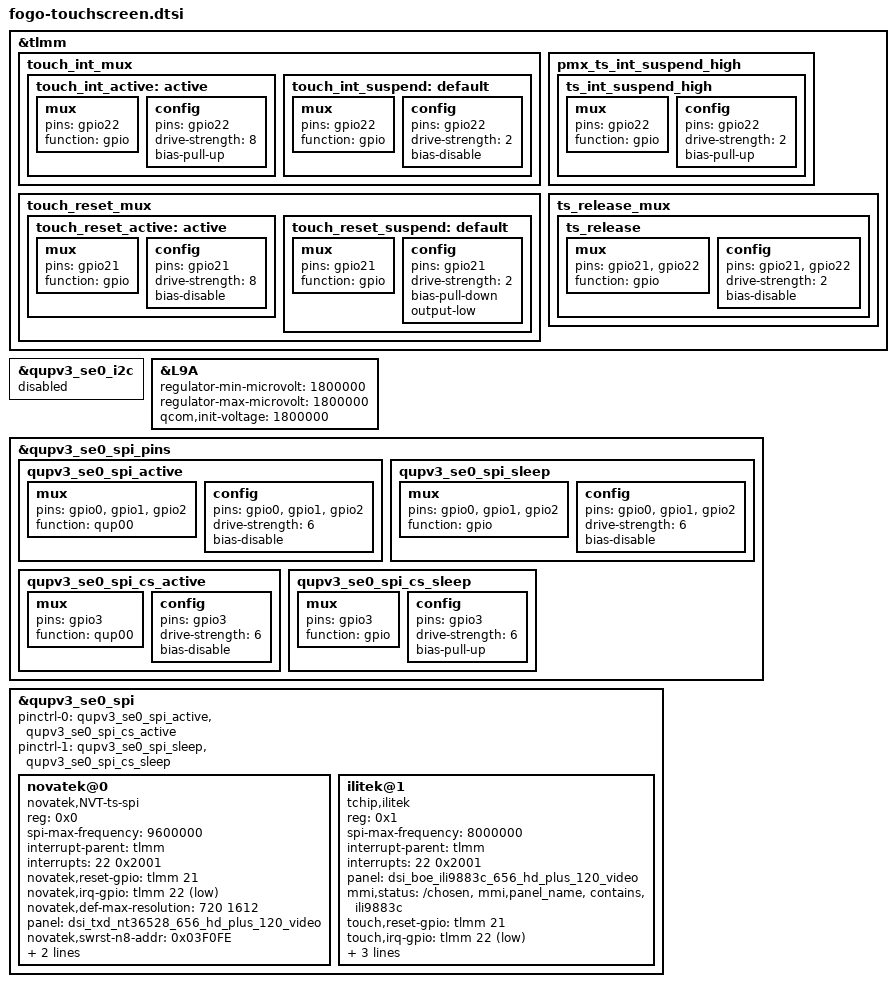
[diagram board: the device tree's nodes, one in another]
/*
 * Copyright (c) 2019, The Linux Foundation. All rights reserved.
 *
 * This program is free software; you can redistribute it and/or modify
 * it under the terms of the GNU General Public License version 2 and
 * only version 2 as published by the Free Software Foundation.
 *
 * This program is distributed in the hope that it will be useful,
 * but WITHOUT ANY WARRANTY; without even the implied warranty of
 * MERCHANTABILITY or FITNESS FOR A PARTICULAR PURPOSE.  See the
 * GNU General Public License for more details.
 */
&tlmm {
	touch_int_mux {
		touch_int_active: active {
			mux {
				pins = "gpio22";
				function = "gpio";
			};
			config {
				pins = "gpio22";
				drive-strength = <8>;
				bias-pull-up;
			};
		};

		touch_int_suspend: default {
			mux {
				pins = "gpio22";
				function = "gpio";
			};
			config {
				pins = "gpio22";
				drive-strength = <2>;
				bias-disable;
			};
		};
	};

	pmx_ts_int_suspend_high {
		ts_int_suspend_high: ts_int_suspend_high {
			mux {
				pins = "gpio22";
				function = "gpio";
			};
			config {
				pins = "gpio22";
				drive-strength = <2>;
				bias-pull-up;
			};
		};
	};

	touch_reset_mux {
		touch_reset_active: active {
			mux {
				pins = "gpio21";
				function = "gpio";
			};
			config {
				pins = "gpio21";
				drive-strength = <8>;
				bias-disable;
			};
		};

		touch_reset_suspend: default {
			mux {
				pins = "gpio21";
				function = "gpio";
			};
			config {
				pins = "gpio21";
				drive-strength = <2>;
				bias-pull-down;
				output-low;
			};
		};
	};

	ts_release_mux {
		ts_release: ts_release {
			mux {
				pins = "gpio21", "gpio22";
				function = "gpio";
			};

			config {
				pins = "gpio21", "gpio22";
				drive-strength = <2>;
				bias-disable;
			};
		};
	};
};

&qupv3_se0_i2c {
	status = "disabled";
};

&L9A {
	regulator-min-microvolt = <1800000>;
	regulator-max-microvolt = <1800000>;
	qcom,init-voltage = <1800000>;
	status = "okay";
};

&qupv3_se0_spi_pins {
	qupv3_se0_spi_active: qupv3_se0_spi_active {
		mux {
			pins = "gpio0", "gpio1", "gpio2";
			function = "qup00";
		};

		config {
			pins = "gpio0", "gpio1", "gpio2";
			drive-strength = <6>;
			bias-disable;
		};
	};

	qupv3_se0_spi_sleep: qupv3_se0_spi_sleep {
		mux {
			pins = "gpio0", "gpio1", "gpio2";
			function = "gpio";
		};

		config {
			pins = "gpio0", "gpio1", "gpio2";
			drive-strength = <6>;
			bias-disable;
		};
	};

	qupv3_se0_spi_cs_active: qupv3_se0_spi_cs_active {
		mux {
			pins = "gpio3";
			function = "qup00";
		};

		config {
			pins = "gpio3";
			drive-strength = <6>;
			bias-disable;
		};
	};

	qupv3_se0_spi_cs_sleep: qupv3_se0_spi_cs_sleep {
		mux {
			pins = "gpio3";
			function = "gpio";
		};

		config {
			pins = "gpio3";
			drive-strength = <6>;
			bias-pull-up;
		};
	};
};

&qupv3_se0_spi {
	status = "ok";
	pinctrl-0 = <&qupv3_se0_spi_active &qupv3_se0_spi_cs_active>;
	pinctrl-1 = <&qupv3_se0_spi_sleep &qupv3_se0_spi_cs_sleep>;

	novatek@0 {
		compatible = "novatek,NVT-ts-spi";
		reg = <0x0>;

		spi-max-frequency = <9600000>;
		interrupt-parent = <&tlmm>;
		interrupts = <22 0x2001>;
		novatek,reset-gpio = <&tlmm 21 0x00>;
		novatek,irq-gpio = <&tlmm 22 0x2001>;
		novatek,def-max-resolution = <720 1612>;
		panel = <&dsi_txd_nt36528_656_hd_plus_120_video>;
		novatek,swrst-n8-addr = <0x03F0FE>;
		novatek,spi-rd-fast-addr = <0x03F310>;
		novatek,usb_charger;
		status = "ok";
	};

	ilitek@1 {
		compatible = "tchip,ilitek";
		reg = <0x1>;
		spi-max-frequency = <8000000>;
		interrupt-parent = <&tlmm>;
		interrupts = <22 0x2001>;
		panel = <&dsi_boe_ili9883c_656_hd_plus_120_video>;
		mmi,status = "/chosen","mmi,panel_name","contains","ili9883c";
		touch,reset-gpio = <&tlmm 21 0x00>;
		touch,irq-gpio = <&tlmm 22 0x2001>;
		pinctrl-names = "pmx_ts_int_active","pmx_ts_int_suspend_high";
		pinctrl-0 = <&ts_active>;
		pinctrl-1 = <&ts_int_suspend_high>;
		ilitek,report_gesture_key;
		status = "ok";
	};
};
